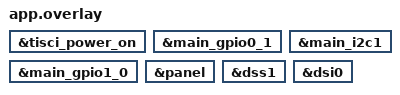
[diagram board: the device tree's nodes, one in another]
/* SPDX-License-Identifier: Apache-2.0 */
/* SPDX-FileCopyrightText: 2026 Signal Slot, Inc. */
/*
 * Toradex Verdin AM62P (board definition). The board DTS has the GPU
 * node with its 64 MiB carveout and the display path wired but disabled
 * (the R5F owns the display in the platform). This stand-alone
 * application drives the panel itself, so it enables DSS1, DSI, the bridge
 * on I2C1, the GPIO banks and the TISCI power-on list.
 */

&tisci_power_on {
	status = "okay";
};

&main_gpio0_1 {
	status = "okay";
};

&main_gpio1_0 {
	status = "okay";
};

&main_i2c1 {
	status = "okay";
};

&panel {
	status = "okay";
};

&dss1 {
	status = "okay";
};

&dsi0 {
	status = "okay";
};
